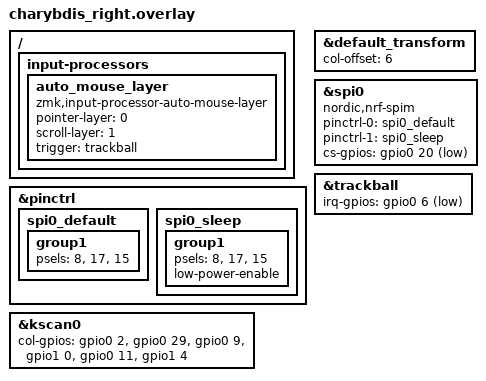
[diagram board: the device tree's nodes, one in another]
/*
 * Copyright (c) 2020 ZMK Contributors
 * SPDX-License-Identifier: MIT
 */

#include "charybdis.dtsi"

&pinctrl {
    spi0_default: spi0_default {
        group1 {
            psels = <8>, <17>, <15>;
        };
    };
    spi0_sleep: spi0_sleep {
        group1 {
            psels = <8>, <17>, <15>;
            low-power-enable;
        };
    };
};


&kscan0 {
    col-gpios = 
        <&gpio0 2 (GPIO_ACTIVE_HIGH | GPIO_PULL_DOWN)>,
        <&gpio0 29 (GPIO_ACTIVE_HIGH | GPIO_PULL_DOWN)>,
        <&gpio0 9 (GPIO_ACTIVE_HIGH | GPIO_PULL_DOWN)>,
        <&gpio1 0 (GPIO_ACTIVE_HIGH | GPIO_PULL_DOWN)>,
        <&gpio0 11 (GPIO_ACTIVE_HIGH | GPIO_PULL_DOWN)>,
        <&gpio1 4 (GPIO_ACTIVE_HIGH | GPIO_PULL_DOWN)>;
};

&default_transform {
    col-offset = <6>;
};

&spi0 {
    status = "okay";
    compatible = "nordic,nrf-spim";
    pinctrl-0 = <&spi0_default>;
    pinctrl-1 = <&spi0_sleep>;
    pinctrl-names = "default", "sleep";
    cs-gpios = <&gpio0 20 GPIO_ACTIVE_LOW>;
};

&trackball {
    status = "okay";
    irq-gpios = <&gpio0 6 (GPIO_ACTIVE_LOW | GPIO_PULL_UP)>;
};

/ {
    input-processors {
        auto_mouse_layer {
            compatible = "zmk,input-processor-auto-mouse-layer";
            pointer-layer = <0>;
            scroll-layer  = <1>;
            trigger = "trackball";
        };
    };
};
